# STM32U5A9 register map
File version: 0.2
CPU: CM33 r0p1, little endian, MPU, FPU, 4 interrupt priority bits
Registers are 32-bit, read-write, reset 0x0 unless marked. A register's access mark holds for its fields unless they carry their own. Offsets are from the block's base; [hi:lo] are bit positions; {n}, {i} and the like mark numbered series.

## RCC (part 3 of 3) — Reset and clock control
Base 0x46020C00
Same registers: SEC_RCC 0x56020C00
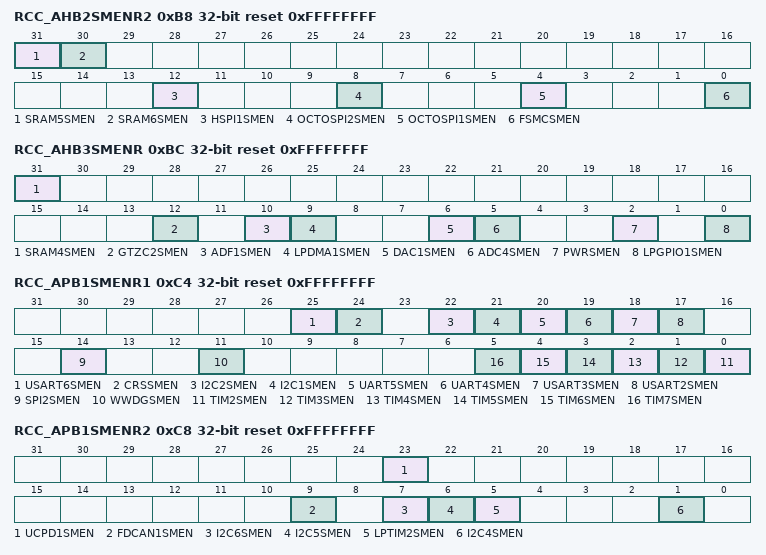
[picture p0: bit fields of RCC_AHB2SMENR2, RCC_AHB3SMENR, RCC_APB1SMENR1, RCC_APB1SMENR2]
0xB8 RCC_AHB2SMENR2 reset 0xFFFFFFFF — RCC AHB2 peripheral clock enable in Sleep and Stop modes register 2
  [31] SRAM5SMEN — SRAM5 clock enable during Sleep and Stop modes This bit is set and cleared by software. Note: This bit is only available on some devices in the STM32U5 Series. Refer to the device datasheet for availability of its associated peripheral. If not present, consider this bit as reserved and keep it at reset value.
  [30] SRAM6SMEN — SRAM6 clock enable during Sleep and Stop modes This bit is set and cleared by software. Note: This bit is only available on some devices in the STM32U5 Series. Refer to the device datasheet for availability of its associated peripheral. If not present, consider this bit as reserved and keep it at reset value.
  [12] HSPI1SMEN — HSPI1 clock enable during Sleep and Stop modes This bit is set and cleared by software. Note: This bit is only available on some devices in the STM32U5 Series. Refer to the device datasheet for availability of its associated peripheral. If not present, consider this bit as reserved and keep it at reset value.
  [8] OCTOSPI2SMEN — OCTOSPI2 clock enable during Sleep and Stop modes This bit is set and cleared by software. Note: This bit is only available on some devices in the STM32U5 Series. Refer to the device datasheet for availability of its associated peripheral. If not present, consider this bit as reserved and keep it at reset value.
  [4] OCTOSPI1SMEN — OCTOSPI1 clock enable during Sleep and Stop modes This bit is set and cleared by software.
  [0] FSMCSMEN — FSMC clock enable during Sleep and Stop modes This bit is set and cleared by software. Note: This bit is only available on some devices in the STM32U5 Series. Refer to the device datasheet for availability of its associated peripheral. If not present, consider this bit as reserved and keep it at reset value.
0xBC RCC_AHB3SMENR reset 0xFFFFFFFF — RCC AHB3 peripheral clock enable in Sleep and Stop modes register
  [31] SRAM4SMEN — SRAM4 clock enable during Sleep and Stop modes This bit is set and cleared by software.
  [12] GTZC2SMEN — GTZC2 clock enable during Sleep and Stop modes This bit is set and cleared by software.
  [10] ADF1SMEN — ADF1 clock enable during Sleep and Stop modes This bit is set and cleared by software. Note: This bit must be set to allow the peripheral to wake up from Stop modes.
  [9] LPDMA1SMEN — LPDMA1 clock enable during Sleep and Stop modes This bit is set and cleared by software. Note: This bit must be set to allow the peripheral to wake up from Stop modes.
  [6] DAC1SMEN — DAC1 clock enable during Sleep and Stop modes This bit is set and cleared by software. Note: This bit must be set to allow the peripheral to wake up from Stop modes.
  [5] ADC4SMEN — ADC4 clock enable during Sleep and Stop modes This bit is set and cleared by software. Note: This bit must be set to allow the peripheral to wake up from Stop modes.
  [2] PWRSMEN — PWR clock enable during Sleep and Stop modes This bit is set and cleared by software.
  [0] LPGPIO1SMEN — LPGPIO1 enable during Sleep and Stop modes This bit is set and cleared by software.
0xC4 RCC_APB1SMENR1 reset 0xFFFFFFFF — RCC APB1 peripheral clock enable in Sleep and Stop modes register 1
  [25] USART6SMEN — USART6 clock enable during Sleep and Stop modes This bit is set and cleared by software. Note: This bit must be set to allow the peripheral to wake up from Stop modes. Note: This bit is only available on some devices in the STM32U5 Series. Refer to the device datasheet for availability of its associated peripheral. If not present, consider this bit as reserved and keep it at reset value.
  [24] CRSSMEN — CRS clock enable during Sleep and Stop modes This bit is set and cleared by software.
  [22] I2C2SMEN — I2C2 clock enable during Sleep and Stop modes This bit is set and cleared by software. Note: This bit must be set to allow the peripheral to wake up from Stop modes.
  [21] I2C1SMEN — I2C1 clock enable during Sleep and Stop modes This bit is set and cleared by software. Note: This bit must be set to allow the peripheral to wake up from Stop modes.
  [20] UART5SMEN — UART5 clock enable during Sleep and Stop modes This bit is set and cleared by software. Note: This bit must be set to allow the peripheral to wake up from Stop modes.
  [19] UART4SMEN — UART4 clock enable during Sleep and Stop modes This bit is set and cleared by software. Note: This bit must be set to allow the peripheral to wake up from Stop modes.
  [18] USART3SMEN — USART3 clock enable during Sleep and Stop modes This bit is set and cleared by software. Note: This bit must be set to allow the peripheral to wake up from Stop modes.
  [17] USART2SMEN — USART2 clock enable during Sleep and Stop modes This bit is set and cleared by software. Note: This bit must be set to allow the peripheral to wake up from Stop modes. Note: This bit is only available on some devices in the STM32U5 Series. Refer to the device datasheet for availability of its associated peripheral. If not present, consider this bit as reserved and keep it at reset value.
  [14] SPI2SMEN — SPI2 clock enable during Sleep and Stop modes This bit is set and cleared by software. Note: This bit must be set to allow the peripheral to wake up from Stop modes.
  [11] WWDGSMEN — Window watchdog clock enable during Sleep and Stop modes This bit is set and cleared by software. It is forced to one by hardware when the hardware WWDG option is activated.
  [n-2] TIM{n}SMEN (n=2..7) — TIM{n} clock enable during Sleep and Stop modes This bit is set and cleared by software.
0xC8 RCC_APB1SMENR2 reset 0xFFFFFFFF — RCC APB1 peripheral clocks enable in Sleep and Stop modes register 2
  [23] UCPD1SMEN — UCPD1 clock enable during Sleep and Stop modes This bit is set and cleared by software. Note: This bit is only available on some devices in the STM32U5 Series. Refer to the device datasheet for availability of its associated peripheral. If not present, consider this bit as reserved and keep it at reset value.
  [9] FDCAN1SMEN — FDCAN1 clock enable during Sleep and Stop modes This bit is set and cleared by software.
  [7] I2C6SMEN — I2C6 clock enable during Sleep and Stop modes This bit is set and cleared by software Note: This bit must be set to allow the peripheral to wake up from Stop modes. Note: This bit is only available on some devices in the STM32U5 Series. Refer to the device datasheet for availability of its associated peripheral. If not present, consider this bit as reserved and keep it at reset value.
  [6] I2C5SMEN — I2C5 clock enable during Sleep and Stop modes This bit is set and cleared by software Note: This bit must be set to allow the peripheral to wake up from Stop modes. Note: This bit is only available on some devices in the STM32U5 Series. Refer to the device datasheet for availability of its associated peripheral. If not present, consider this bit as reserved and keep it at reset value.
  [5] LPTIM2SMEN — LPTIM2 clock enable during Sleep and Stop modes This bit is set and cleared by software. Note: This bit must be set to allow the peripheral to wake up from Stop modes.
  [1] I2C4SMEN — I2C4 clock enable during Sleep and Stop modes This bit is set and cleared by software Note: This bit must be set to allow the peripheral to wake up from Stop modes.
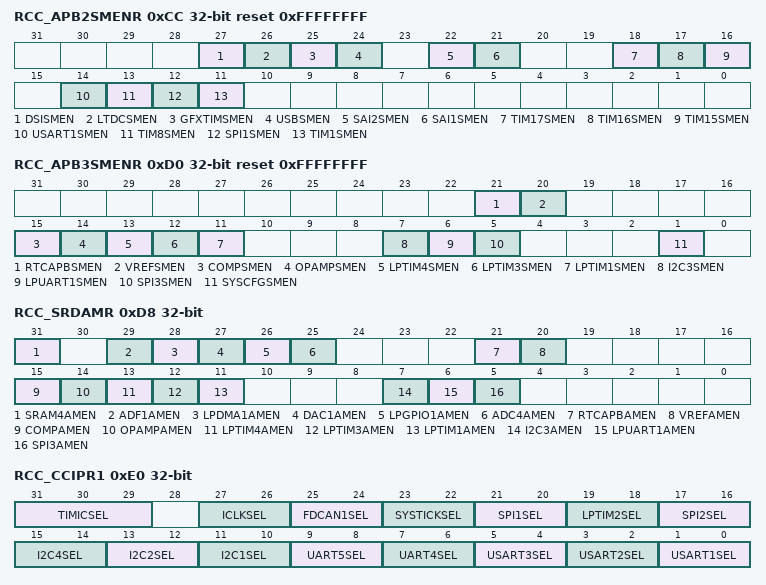
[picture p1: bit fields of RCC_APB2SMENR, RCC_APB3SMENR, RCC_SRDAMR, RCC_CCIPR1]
0xCC RCC_APB2SMENR reset 0xFFFFFFFF — RCC APB2 peripheral clocks enable in Sleep and Stop modes register
  [27] DSISMEN — DSI clock enable during Sleep and Stop modes This bit is set and cleared by software. Note: This bit is only available on some devices in the STM32U5 Series. Refer to the device datasheet for availability of its associated peripheral. If not present, consider this bit as reserved and keep it at reset value.
  [26] LTDCSMEN — LTDC clock enable during Sleep and Stop modes This bit is set and cleared by software. Note: This bit is only available on some devices in the STM32U5 Series. Refer to the device datasheet for availability of its associated peripheral. If not present, consider this bit as reserved and keep it at reset value.
  [25] GFXTIMSMEN — GFXTIM clock enable during Sleep and Stop modes This bit is set and cleared by software. Note: This bit is only available on some devices in the STM32U5 Series. Refer to the device datasheet for availability of its associated peripheral. If not present, consider this bit as reserved and keep it at reset value.
  [24] USBSMEN — USB clock enable during Sleep and Stop modes This bit is set and cleared by software. Note: This bit is only available on some devices in the STM32U5 Series. Refer to the device datasheet for availability of its associated peripheral. If not present, consider this bit as reserved and keep it at reset value.
  [22] SAI2SMEN — SAI2 clock enable during Sleep and Stop modes This bit is set and cleared by software. Note: This bit is only available on some devices in the STM32U5 Series.Refer to the device datasheet for availability of its associated peripheral. If not present, consider this bit as reserved and keep it at reset value.
  [21] SAI1SMEN — SAI1 clock enable during Sleep and Stop modes This bit is set and cleared by software.
  [18] TIM17SMEN — TIM17 clock enable during Sleep and Stop modes This bit is set and cleared by software.
  [17] TIM16SMEN — TIM16 clock enable during Sleep and Stop modes This bit is set and cleared by software.
  [16] TIM15SMEN — TIM15 clock enable during Sleep and Stop modes This bit is set and cleared by software.
  [14] USART1SMEN — USART1 clock enable during Sleep and Stop modes This bit is set and cleared by software. Note: This bit must be set to allow the peripheral to wake up from Stop modes.
  [13] TIM8SMEN — TIM8 clock enable during Sleep and Stop modes This bit is set and cleared by software.
  [12] SPI1SMEN — SPI1 clock enable during Sleep and Stop modes This bit is set and cleared by software. Note: This bit must be set to allow the peripheral to wake up from Stop modes.
  [11] TIM1SMEN — TIM1 clock enable during Sleep and Stop modes This bit is set and cleared by software.
0xD0 RCC_APB3SMENR reset 0xFFFFFFFF — RCC APB3 peripheral clock enable in Sleep and Stop modes register
  [21] RTCAPBSMEN — RTC and TAMP APB clock enable during Sleep and Stop modes This bit is set and cleared by software. Note: This bit must be set to allow the peripheral to wake up from Stop modes.
  [20] VREFSMEN — VREFBUF clock enable during Sleep and Stop modes This bit is set and cleared by software.
  [15] COMPSMEN — COMP clock enable during Sleep and Stop modes This bit is set and cleared by software.
  [14] OPAMPSMEN — OPAMP clock enable during Sleep and Stop modes This bit is set and cleared by software.
  [13] LPTIM4SMEN — LPTIM4 clock enable during Sleep and Stop modes This bit is set and cleared by software. Note: This bit must be set to allow the peripheral to wake up from Stop modes.
  [12] LPTIM3SMEN — LPTIM3 clock enable during Sleep and Stop modes This bit is set and cleared by software. Note: This bit must be set to allow the peripheral to wake up from Stop modes.
  [11] LPTIM1SMEN — LPTIM1 clock enable during Sleep and Stop modes This bit is set and cleared by software. Note: This bit must be set to allow the peripheral to wake up from Stop modes.
  [7] I2C3SMEN — I2C3 clock enable during Sleep and Stop modes This bit is set and cleared by software. Note: This bit must be set to allow the peripheral to wake up from Stop modes.
  [6] LPUART1SMEN — LPUART1 clock enable during Sleep and Stop modes This bit is set and cleared by software. Note: This bit must be set to allow the peripheral to wake up from Stop modes.
  [5] SPI3SMEN — SPI3 clock enable during Sleep and Stop modes This bit is set and cleared by software. Note: This bit must be set to allow the peripheral to wake up from Stop modes.
  [1] SYSCFGSMEN — SYSCFG clock enable during Sleep and Stop modes This bit is set and cleared by software.
0xD8 RCC_SRDAMR — RCC SmartRun domain peripheral autonomous mode register
  [31] SRAM4AMEN — SRAM4 autonomous mode enable in Stop 0/1/2 mode This bit is set and cleared by software.
  [29] ADF1AMEN — ADF1 autonomous mode enable in Stop 0/1/2 mode This bit is set and cleared by software. Note: This bit must be set to allow the peripheral to wake up from Stop modes.
  [28] LPDMA1AMEN — LPDMA1 autonomous mode enable in Stop 0/1/2 mode This bit is set and cleared by software. Note: This bit must be set to allow the peripheral to wake up from Stop modes.
  [27] DAC1AMEN — DAC1 autonomous mode enable in Stop 0/1/2 mode This bit is set and cleared by software. Note: This bit must be set to allow the peripheral to wake up from Stop modes.
  [26] LPGPIO1AMEN — LPGPIO1 autonomous mode enable in Stop 0/1/2 mode This bit is set and cleared by software.
  [25] ADC4AMEN — ADC4 autonomous mode enable in Stop 0/1/2 mode This bit is set and cleared by software. Note: This bit must be set to allow the peripheral to wake up from Stop modes.
  [21] RTCAPBAMEN — RTC and TAMP autonomous mode enable in Stop 0/1/2 mode This bit is set and cleared by software. Note: This bit must be set to allow the peripheral to wake up from Stop modes.
  [20] VREFAMEN — VREFBUF autonomous mode enable in Stop 0/1/2 mode This bit is set and cleared by software.
  [15] COMPAMEN — COMP autonomous mode enable in Stop 0/1/2 mode This bit is set and cleared by software.
  [14] OPAMPAMEN — OPAMP autonomous mode enable in Stop 0/1/2 mode This bit is set and cleared by software.
  [13] LPTIM4AMEN — LPTIM4 autonomous mode enable in Stop 0/1/2 mode This bit is set and cleared by software. Note: This bit must be set to allow the peripheral to wake up from Stop modes.
  [12] LPTIM3AMEN — LPTIM3 autonomous mode enable in Stop 0/1/2 mode This bit is set and cleared by software. Note: This bit must be set to allow the peripheral to wake up from Stop modes.
  [11] LPTIM1AMEN — LPTIM1 autonomous mode enable in Stop 0/1/2 mode This bit is set and cleared by software. Note: This bit must be set to allow the peripheral to wake up from Stop modes.
  [7] I2C3AMEN — I2C3 autonomous mode enable in Stop 0/1/2 mode This bit is set and cleared by software. Note: This bit must be set to allow the peripheral to wake up from Stop modes.
  [6] LPUART1AMEN — LPUART1 autonomous mode enable in Stop 0/1/2 mode This bit is set and cleared by software. Note: This bit must be set to allow the peripheral to wake up from Stop modes.
  [5] SPI3AMEN — SPI3 autonomous mode enable in Stop 0,1, 2 mode This bit is set and cleared by software. Note: This bit must be set to allow the peripheral to wake up from Stop modes.
0xE0 RCC_CCIPR1 — RCC peripherals independent clock configuration register 1
  [31:29] TIMICSEL — Clock sources for TIM16,TIM17, and LPTIM2 internal input capture When TIMICSEL2 is set, the TIM16, TIM17, and LPTIM2 internal input capture can be connected either to HSI/256, MSI/4, or MSI/1024. Depending on TIMICSEL[1:0] value, MSI is either MSIK or MSIS. When TIMICSEL2 is cleared, the HSI, MSIK, and MSIS clock sources cannot be selected as�TIM16, TIM17, or LPTIM2 internal input capture. 0xx: HSI, MSIK and MSIS dividers disabled Note: The clock division must be disabled (TIMICSEL configured to 0xx) before selecting or changing a clock sources division.
  [27:26] ICLKSEL — Intermediate clock source selection These bits are used to select the clock source for the OTG_FS, the USB, and the SDMMC.
  [25:24] FDCAN1SEL — FDCAN1 kernel clock source selection These bits are used to select the FDCAN1 kernel clock source.
  [23:22] SYSTICKSEL — SysTick clock source selection These bits are used to select the SysTick clock source. Note: When LSE or LSI is selected, the AHB frequency must be at least four times higher than the LSI or LSE frequency. In addition, a jitter up to one HCLK cycle is introduced, due to the LSE or LSI sampling with HCLK in the SysTick circuitry.
  [21:20] SPI1SEL — SPI1 kernel clock source selection These bits are used to select the SPI1 kernel clock source. Note: The SPI1 is functional in Stop 0 and Stop 1 mode only when the kernel clock is HSI16 or MSIK.
  [19:18] LPTIM2SEL — Low-power timer 2 kernel clock source selection These bits are used to select the LPTIM2 kernel clock source. Note: The LPTIM2 is functional in Stop 0 and Stop 1 mode only when the kernel clock is LSI, LSE or HSI16 if HSIKERON = 1.
  [17:16] SPI2SEL — SPI2 kernel clock source selection These bits are used to select the SPI2 kernel clock source. Note: The SPI2 is functional in Stop 0 and Stop 1 mode only when the kernel clock is HSI16 or MSIK.
  [15:14] I2C4SEL — I2C4 kernel clock source selection These bits are used to select the I2C4 kernel clock source. Note: The I2C4 is functional in Stop 0 and Stop 1 modes only when the kernel clock is HSI16�or MSIK.
  [13:12] I2C2SEL — I2C2 kernel clock source selection These bits are used to select the I2C2 kernel clock source. Note: The I2C2 is functional in Stop 0 and Stop 1 mode sonly when the kernel clock is HSI16�or MSIK.
  [11:10] I2C1SEL — I2C1 kernel clock source selection These bits are used to select the I2C1 kernel clock source. Note: The I2C1 is functional in Stop 0 and Stop 1 mode sonly when the kernel clock is HSI16�or MSIK.
  [9:8] UART5SEL — UART5 kernel clock source selection These bits are used to select the UART5 kernel clock source. Note: The UART5 is functional in Stop 0 and Stop 1 modes only when the kernel clock is HSI16 or LSE.
  [7:6] UART4SEL — UART4 kernel clock source selection These bits are used to select the UART4 kernel clock source. Note: The UART4 is functional in Stop 0 and Stop 1 modes only when the kernel clock is HSI16 or LSE.
  [5:4] USART3SEL — USART3 kernel clock source selection These bits are used to select the USART3 kernel clock source. Note: The USART3 is functional in Stop 0 and Stop 1 modes only when the kernel clock is HSI16 or LSE.
  [3:2] USART2SEL — USART2 kernel clock source selection These bits are used to select the USART2 kernel clock source. The USART2 is functional in Stop 0 and Stop 1 modes only when the kernel clock is HSI16 or LSE. Note: This bitfield is only available on some devices in the STM32U5 Series. Refer to the device datasheet for availability of its associated peripheral. If not present, consider this bitfield as reserved and keep it at reset value.
  [1:0] USART1SEL — USART1 kernel clock source selection These bits are used to select the USART1 kernel clock source. Note: The USART1 is functional in Stop 0 and Stop 1 modes only when the kernel clock is HSI16 or LSE.
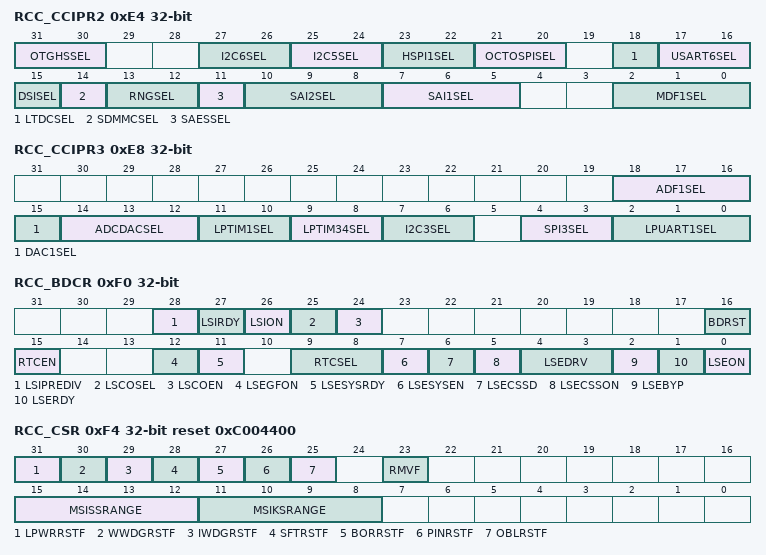
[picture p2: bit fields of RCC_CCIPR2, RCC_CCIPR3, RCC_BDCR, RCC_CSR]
0xE4 RCC_CCIPR2 — RCC peripherals independent clock configuration register 2
  [31:30] OTGHSSEL — OTG_HS PHY kernel clock source selection These bits are used to select the OTG_HS PHY kernel clock source. Note: This bitfield is only available on some devices in the STM32U5 Series. Refer to the device datasheet for availability of its associated peripheral. If not present, consider this bitfield as reserved and keep it at reset value.
  [27:26] I2C6SEL — I2C6 kernel clock source selection These bits are used to select the I2C6 kernel clock source. The I2C6 is functional in Stop 0 and Stop 1 modes only when the kernel clock is HSI16�or MSIK. Note: This bitfield is only available on some devices in the STM32U5 Series. Refer to the device datasheet for availability of its associated peripheral. If not present, consider this bitfield as reserved and keep it at reset value.
  [25:24] I2C5SEL — I2C5 kernel clock source selection These bits are used to select the I2C5 kernel clock source. The I2C5 is functional in Stop 0 and Stop 1 modes only when the kernel clock is HSI16�or MSIK. Note: This bitfield is only available on some devices in the STM32U5 Series. Refer to the device datasheet for availability of its associated peripheral. If not present, consider this bitfield as reserved and keep it at reset value.
  [23:22] HSPI1SEL — HSPI1 kernel clock source selection These bits are used to select the HSPI1 kernel clock source. Note: This bitfield is only available on some devices in the STM32U5 Series. Refer to the device datasheet for availability of its associated peripheral. If not present, consider this bitfield as reserved and keep it at reset value.
  [21:20] OCTOSPISEL — OCTOSPI1 and OCTOSPI2 kernel clock source selection These bits are used to select the OCTOSPI1 and OCTOSPI2 kernel clock source.
  [18] LTDCSEL — LTDC kernel clock source selection This bit is used to select the LTDC kernel clock source. Note: This bit is only available on some devices in the STM32U5 Series. Refer to the device datasheet for availability of its associated peripheral. If not present, consider this bit as reserved and keep it at reset value.
  [17:16] USART6SEL — USART6 kernel clock source selection These bits are used to select the USART6 kernel clock source. The USART6 is functional in Stop 0 and Stop 1 modes only when the kernel clock is HSI16 or LSE. Note: This bitfield is only available on some devices in the STM32U5 Series. Refer to the device datasheet for availability of its associated peripheral. If not present, consider this bitfield as reserved and keep it at reset value.
  [15] DSISEL — DSI kernel clock source selection This bit is used to select the DSI kernel clock source. This bit is only available on some devices in the STM32U5 Series. Refer to the device datasheet for availability of its associated peripheral. Note: If not present, consider this bit as reserved and keep it at reset value.
  [14] SDMMCSEL — SDMMC1 and SDMMC2 kernel clock source selection This bit is used to select the SDMMC kernel clock source. It is recommended to change it only after reset and before enabling the SDMMC.
  [13:12] RNGSEL — RNG kernel clock source selection These bits are used to select the RNG kernel clock source.
  [11] SAESSEL — SAES kernel clock source selection This bit is used to select the SAES kernel clock source. Note: This bit is only available on some devices in the STM32U5 Series. Refer to the device datasheet for availability of its associated peripheral. If not present, consider this bit as reserved and keep it at reset value.
  [10:8] SAI2SEL — SAI2 kernel clock source selection These bits are used to select the SAI2 kernel clock source. others: reserved If the selected clock is the external clock and this clock is stopped, a switch to another clock is impossible. Note: This bitfield is only available on some devices in the STM32U5 Series. Refer to the device datasheet for availability of its associated peripheral. If not present, consider this bitfield as reserved and keep it at reset value.
  [7:5] SAI1SEL — SAI1 kernel clock source selection These bits are used to select the SAI1 kernel clock source. others: reserved Note: If the selected clock is the external clock and this clock is stopped, a switch to another clock is impossible.
  [2:0] MDF1SEL — MDF1 kernel clock source selection These bits are used to select the MDF1 kernel clock source. others: reserved
0xE8 RCC_CCIPR3 — RCC peripherals independent clock configuration register 3
  [18:16] ADF1SEL — ADF1 kernel clock source selection These bits are used to select the ADF1 kernel clock source. others: reserved Note: The ADF1 is functional in Stop 0, Stop 1, and Stop 2 modes only when the kernel clock is AUDIOCLK or MSIK.
  [15] DAC1SEL — DAC1 sample-and-hold clock source selection This bit is used to select the DAC1 sample-and-hold clock source.
  [14:12] ADCDACSEL — ADC1, ADC2, ADC4 and DAC1 kernel clock source selection These bits are used to select the ADC1, ADC2, ADC4, and DAC1 kernel clock source. others: reserved Note: The ADC1, ADC2, ADC4, and DAC1 are functional in Stop 0, Stop 1, and Stop 2 modes only when the kernel clock is HSI16 or MSIK (only ADC4 and DAC1 are functional in�Stop 2 mode).
  [11:10] LPTIM1SEL — LPTIM1 kernel clock source selection These bits are used to select the LPTIM1 kernel clock source. Note: The LPTIM1 is functional in Stop 0, Stop 1, and Stop 2 modes only when the kernel clock is LSI, LSE, HSI16 with HSIKERON = 1, or MSIK with MSIKERON = 1.
  [9:8] LPTIM34SEL — LPTIM3 and LPTIM4 kernel clock source selection These bits are used to select the LPTIM3 and LPTIM4 kernel clock source. Note: The LPTIM3 and LPTIM4 are functional in Stop 0, Stop 1, and Stop 2 modes only when the kernel clock is LSI, LSE, HSI16 with HSIKERON = 1, or MSIK with MSIKERON�=�1.
  [7:6] I2C3SEL — I2C3 kernel clock source selection These bits are used to select the I2C3 kernel clock source. Note: The I2C3 is functional in Stop 0, Stop 1, and Stop 2 modes only when the kernel clock is HSI16 or MSIK.
  [4:3] SPI3SEL — SPI3 kernel clock source selection These bits are used to select the SPI3 kernel clock source. Note: The SPI3 is functional in Stop 0, Stop 1, and Stop 2 modes only when the kernel clock is HSI16 or MSIK.
  [2:0] LPUART1SEL — LPUART1 kernel clock source selection These bits are used to select the LPUART1 kernel clock source. others: reserved Note: The LPUART1 is functional in Stop 0, Stop 1, and Stop 2 modes only when the kernel clock is HSI16, LSE, or MSIK.
0xF0 RCC_BDCR access per field — RCC backup domain control register
  [28] LSIPREDIV rw — Low-speed clock divider configuration This bit is set and cleared by software to enable the LSI division. It can be written only when the LSI is disabled (LSION = 0 and LSIRDY = 0). If the LSI was previously enabled, it is necessary to wait for at least 60 μs after clearing LSION bit (synchronization time for LSI to be really disabled), before writing LSIPREDIV. The LSIPREDIV cannot be changed if the LSI is used by the IWDG or by the RTC.
  [27] LSIRDY rw — LSI oscillator ready This bit is set and cleared by hardware to indicate when the LSI oscillator is stable. After�LSION is cleared, LSIRDY goes low after three internal low-speed oscillator clock cycles. This bit is set when the LSI is used by IWDG or RTC, even if LSION = 0.
  [26] LSION rw — LSI oscillator enable This bit is set and cleared by software. The LSI oscillator is disabled 60��s maximum after the LSION bit is cleared.
  [25] LSCOSEL rw — Low-speed clock output selection This bit is set and cleared by software.
  [24] LSCOEN rw — Low-speed clock output (LSCO) enable This bit is set and cleared by software.
  [16] BDRST rw — Backup domain software reset This bit is set and cleared by software.
  [15] RTCEN rw — RTC and TAMP clock enable This bit is set and cleared by software.
  [12] LSEGFON rw — LSE clock glitch filter enable This bit is set and cleared by hardware to enable the LSE glitch filter. It can be written only when the LSE is disabled (LSEON = 0 and LSERDY = 0).
  [11] LSESYSRDY ro — LSE system clock (LSESYS) ready This bit is set and cleared by hardware to indicate when the LSE system clock is stable.When LSESYSEN is set, this LSESYSRDY flag is set after two LSE clock cycles. The LSE clock must be already enabled and stable (LSEON and LSERDY are set). When the LSEON bit is cleared, LSERDY goes low after six external low-speed oscillator clock cycles.
  [9:8] RTCSEL rw — RTC and TAMP clock source selection This bit is set by software to select the clock source for the RTC and TAMP. Once the RTC and TAMP clock source has been selected, it cannot be changed anymore unless the�backup domain is reset, or unless a failure is detected on LSE (LSECSSD is set). BDRST bit can be used to reset them.
  [7] LSESYSEN rw — LSE system clock (LSESYS) enable This bit is set by software to enable always the LSE system clock generated by RCC, which can be used by any peripheral when its source clock is the LSE, or at system level if one of LSCOSEL, MCO, or MSI PLL mode is needed.
  [6] LSECSSD ro — CSS on LSE failure detection This bit is set by hardware to indicate when a failure is detected by the CCS on the external 32�kHz oscillator (LSE).
  [5] LSECSSON rw — CSS on LSE enable This bit is set by software to enable the CSS on LSE. It must be enabled after the LSE oscillator is enabled (LSEON bit enabled) and ready (LSERDY flag set by hardware), and after the RTCSEL bit is selected. Once enabled, this bit cannot be disabled, except after a LSE failure detection (LSECSSD�=�1). In that case, the software must disable this LSECSSON bit.
  [4:3] LSEDRV rw — LSE oscillator drive capability This bitfield is set by software to modulate the drive capability of the LSE oscillator. It can be written only when the external 32 kHz oscillator is disabled (LSEON = 0 and LSERDY = 0). Note: The oscillator is in ‘Xtal mode’ when it is not in bypass mode.
  [2] LSEBYP rw — LSE oscillator bypass This bit is set and cleared by software to bypass oscillator in debug mode. It can be written only when the external 32�kHz oscillator is disabled (LSEON = 0 and LSERDY = 0).
  [1] LSERDY ro — LSE oscillator ready This bit is set and cleared by hardware to indicate when the external 32�kHz oscillator is stable. After LSEON is cleared, this LSERDY bit goes low after six external low-speed oscillator clock cycles.
  [0] LSEON rw — LSE oscillator enable This bit is set and cleared by software.
0xF4 RCC_CSR access per field reset 0xC004400 — RCC control/status register
  [31] LPWRRSTF ro — Low-power reset flag This bit is set by hardware when a reset occurs due to a Stop, Standby, or Shutdown mode entry, whereas the corresponding NRST_STOP, NRST_STBY, or NRST_SHDW option bit is cleared. This bit is cleared by writing to the RMVF bit.
  [30] WWDGRSTF ro — Window watchdog reset flag This bit is set by hardware when a window watchdog reset occurs. It is cleared by writing to�the RMVF bit.
  [29] IWDGRSTF ro — Independent watchdog reset flag This bit is set by hardware when an independent watchdog reset domain occurs. It is cleared by writing to the RMVF bit.
  [28] SFTRSTF ro — Software reset flag This bit is set by hardware when a software reset occurs. It is cleared by writing to RMVF.
  [27] BORRSTF ro — Brownout reset or an exit from Shutdown mode reset flag This bit is set by hardware when a brownout reset or an exit from Shutdown mode reset occurs. It is cleared by writing to the RMVF bit.
  [26] PINRSTF ro — NRST pin reset flag This bit is set by hardware when a reset from the NRST pin occurs. It is cleared by writing to�the RMVF bit.
  [25] OBLRSTF ro — Option-byte loader reset flag This bit is set by hardware when a reset from the option-byte loading occurs. It is cleared by�writing to the RMVF bit.
  [23] RMVF rw — Remove reset flag This bit is set by software to clear the reset flags.
  [15:12] MSISSRANGE rw — MSIS range after Standby mode This bitfield is set by software to chose the MSIS frequency at startup. It is used after exiting Standby mode until MSIRGSEL is set. After a NRST pin or a power-on reset or when exiting Shutdown mode, the range is always 4�MHz. MSISSRANGE can be written only when MSIRGSEL = 1. others: reserved Note: Changing this bitfield does not change the current MSIS frequency.
  [11:8] MSIKSRANGE rw — MSIK range after Standby mode This bit is set by software to chose the MSIK frequency at startup. It is used after exiting Standby mode until MSIRGSEL is set. After a NRST pin or a power-on reset or when exiting Shutdown mode, the range is always 4�MHz. MSIKSRANGE can be written only when MSIRGSEL = 1. others: reserved Note: Changing this bitfield does not change the current MSIK frequency.
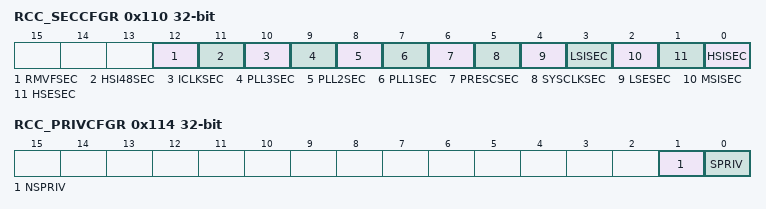
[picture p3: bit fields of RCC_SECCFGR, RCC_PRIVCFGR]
0x110 RCC_SECCFGR — RCC secure configuration register
  [12] RMVFSEC — Remove reset flag security This bit is set and reset by software.
  [11] HSI48SEC — HSI48 clock configuration and status bit security This bit is set and reset by software.
  [10] ICLKSEC — Intermediate clock source selection security This bit is set and reset by software.
  [9] PLL3SEC — PLL3 clock configuration and status bit security This bit is set and reset by software.
  [8] PLL2SEC — PLL2 clock configuration and status bit security Set and reset by software.
  [7] PLL1SEC — PLL1 clock configuration and status bit security This bit is set and reset by software.
  [6] PRESCSEC — AHBx/APBx prescaler configuration bits security This bit is set and reset by software.
  [5] SYSCLKSEC — SYSCLK clock selection, STOPWUCK bit, clock output on MCO configuration security This bit is set and reset by software.
  [4] LSESEC — LSE clock configuration and status bit security This bit is set and reset by software.
  [3] LSISEC — LSI clock configuration and status bit security This bit is set and reset by software.
  [2] MSISEC — MSI clock configuration and status bit security This bit is set and reset by software.
  [1] HSESEC — HSE clock configuration bits, status bit and HSE_CSS security This bit is set and reset by software.
  [0] HSISEC — HSI clock configuration and status bit security This bit is set and reset by software.
0x114 RCC_PRIVCFGR — RCC privilege configuration register
  [1] NSPRIV — RCC non-secure function privilege configuration This bit is set and reset by software. It can be written only by privileged access, secure or non-secure.
  [0] SPRIV — RCC secure function privilege configuration This bit is set and reset by software. It can be written only by a secure privileged access.
